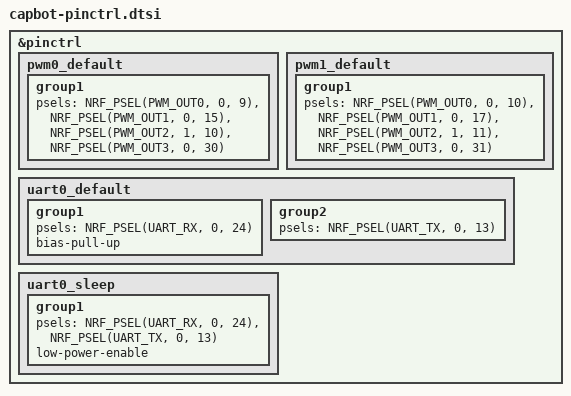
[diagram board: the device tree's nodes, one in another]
// Pin mapping for CapBot

&pinctrl {
    pwm0_default: pwm0_default {
        group1 {
            psels = <NRF_PSEL(PWM_OUT0, 0, 9)>,
                    <NRF_PSEL(PWM_OUT1, 0, 15)>,
                    <NRF_PSEL(PWM_OUT2, 1, 10)>,
                    <NRF_PSEL(PWM_OUT3, 0, 30)>;
        };
    };

    pwm1_default: pwm1_default {
        group1 {
            psels = <NRF_PSEL(PWM_OUT0, 0, 10)>,
                    <NRF_PSEL(PWM_OUT1, 0, 17)>,
                    <NRF_PSEL(PWM_OUT2, 1, 11)>,
                    <NRF_PSEL(PWM_OUT3, 0, 31)>;
        };
    };

    uart0_default: uart0_default {
        group1 {
            psels = <NRF_PSEL(UART_RX, 0, 24)>;
            bias-pull-up;
        };
        group2 {
            psels = <NRF_PSEL(UART_TX, 0, 13)>;
        };
    };

    uart0_sleep: uart0_sleep {
        group1 {
            psels = <NRF_PSEL(UART_RX, 0, 24)>,
                    <NRF_PSEL(UART_TX, 0, 13)>;
            low-power-enable;
        };
    };
};
